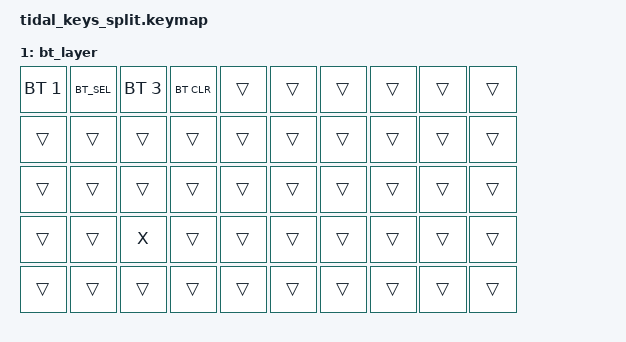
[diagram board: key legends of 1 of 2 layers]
// This file was generated from a template. Edit it to match your keyboard.
// See https://zmk.dev/docs/development/hardware-integration/new-shield for more instructions.

#include <behaviors.dtsi>
#include <dt-bindings/zmk/keys.h>
#include <dt-bindings/zmk/bt.h>

/ {
    combos {
        compatible = "zmk,combos";
        combo_esc {
            timeout-ms = <100>;
            key-positions = <30 24>;
            bindings = <&mo 1>;
        };
    };
};

/ {
    // Define a default keymap here.
    // See https://zmk.dev/docs/development/hardware-integration/new-shield#default-keymap.
    keymap {
        compatible = "zmk,keymap";

        default_layer {
            bindings = <
                &kp N1 &kp N2 &kp N3 &kp N4 &kp N5            &kp N6  &kp N7 &kp N8  &kp N9 &kp N0  
                &kp Q  &kp W  &kp E  &kp R  &kp T             &kp Y   &kp U  &kp I   &kp O  &kp P 
                &kp A  &kp S  &kp D  &kp F  &kp G             &kp H   &kp J  &kp K   &kp L  &kp SEMI
                &kp LSHIFT  &kp Z  &kp X  &kp C  &kp V        &kp B   &kp N  &kp M   &kp BSPC  &kp ENTER
                &kt CAPS   &none  &kp LALT  &kp SPACE         &kp SPACE  &none  &kp COMMA  &kp DOT  &kp RSHIFT
            >;
        };
        bt_layer {
            bindings = <
                &bt BT_SEL 1 &kp BT_SEL 2 &bt BT_SEL 3 &bt BT_CLR &trans      &trans  &trans &trans  &trans &trans
                &trans  &trans &trans  &trans  &trans                         &trans   &trans &trans &trans  &trans 
                &trans  &trans &trans &trans  &trans                          &trans   &trans  &trans   &trans  &trans
                &trans  &trans  &kp X  &trans &trans                          &trans   &trans  &trans   &trans  &trans
                &trans  &trans  &trans &trans &trans                          &trans  &trans  &trans  &trans  &trans
            >;
        };
    };
};
